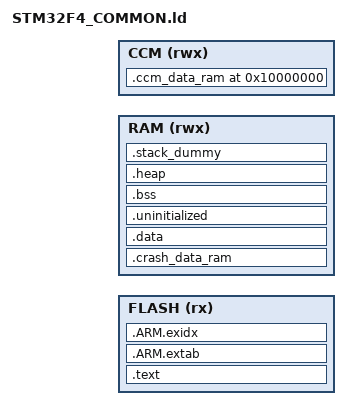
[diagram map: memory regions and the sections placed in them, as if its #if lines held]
/**
 * Copyright (c) 2026 MbedCE Community Contributors (Jan Kamidra)
 * SPDX-License-Identifier: Apache-2.0
 *
 * Licensed under the Apache License, Version 2.0 (the "License");
 * you may not use this file except in compliance with the License.
 * You may obtain a copy of the License at
 *
 *     http://www.apache.org/licenses/LICENSE-2.0
 *
 * Unless required by applicable law or agreed to in writing, software
 * distributed under the License is distributed on an "AS IS" BASIS,
 * WITHOUT WARRANTIES OR CONDITIONS OF ANY KIND, either express or implied.
 * See the License for the specific language governing permissions and
 * limitations under the License.
 *
 * Created by: Jan Kamidra with GitHub Copilot
 */

#include "cmsis_nvic.h"

M_CRASH_DATA_RAM_SIZE = 0x100;

#if !defined(MBED_CONF_TARGET_BOOT_STACK_SIZE)
    /* This value is normally defined by the tools
       to 0x1000 for bare metal and 0x400 for RTOS */
    #define MBED_CONF_TARGET_BOOT_STACK_SIZE  0x400
#endif
STACK_SIZE = MBED_CONF_TARGET_BOOT_STACK_SIZE;

/* Round up MBED_VECTTABLE_RAM_SIZE to 8 bytes */
#define MBED_VECTTABLE_RAM_SIZE  (((NVIC_NUM_VECTORS * 4) + 7) & 0xFFFFFFF8)


MEMORY
{
    FLASH (rx) : ORIGIN = MBED_CONFIGURED_ROM_BANK_ROM_START, LENGTH = MBED_CONFIGURED_ROM_BANK_ROM_SIZE
    RAM (rwx)  : ORIGIN = MBED_RAM_BANK_SRAM_START + MBED_VECTTABLE_RAM_SIZE, LENGTH = MBED_RAM_BANK_SRAM_SIZE - MBED_VECTTABLE_RAM_SIZE
#if defined(CMM_RAM)  
    CCM (rwx)  : ORIGIN = MBED_CONFIGURED_RAM_BANK_CCM_RAM_START, LENGTH = MBED_CONFIGURED_RAM_BANK_CCM_RAM_SIZE
#endif
}

/* Linker script to place sections and symbol values. Should be used together
 * with other linker script that defines memory regions FLASH and RAM.
 * It references following symbols, which must be defined in code:
 *   Reset_Handler : Entry of reset handler
 *
 * It defines following symbols, which code can use without definition:
 *   __exidx_start
 *   __exidx_end
 *   __etext
 *   __data_start__
 *   __preinit_array_start
 *   __preinit_array_end
 *   __init_array_start
 *   __init_array_end
 *   __fini_array_start
 *   __fini_array_end
 *   __data_end__
 *   __bss_start__
 *   __bss_end__
 *   __end__
 *   end
 *   __HeapLimit
 *   __StackLimit
 *   __StackTop
 *   __stack
 *   _estack
 */
ENTRY(Reset_Handler)

SECTIONS
{
    .text :
    {
        KEEP(*(.isr_vector))
        *(.text*)

        KEEP(*(.init))
        KEEP(*(.fini))

        /* .ctors */
        *crtbegin.o(.ctors)
        *crtbegin?.o(.ctors)
        *(EXCLUDE_FILE(*crtend?.o *crtend.o) .ctors)
        *(SORT(.ctors.*))
        *(.ctors)

        /* .dtors */
        *crtbegin.o(.dtors)
        *crtbegin?.o(.dtors)
        *(EXCLUDE_FILE(*crtend?.o *crtend.o) .dtors)
        *(SORT(.dtors.*))
        *(.dtors)

        *(.rodata*)

        KEEP(*(.eh_frame*))
    } > FLASH

    .ARM.extab :
    {
        *(.ARM.extab* .gnu.linkonce.armextab.*)
    } > FLASH

    __exidx_start = .;
    .ARM.exidx :
    {
        *(.ARM.exidx* .gnu.linkonce.armexidx.*)
    } > FLASH
    __exidx_end = .;

    __etext = .;
    _sidata = .;

    /**
     * CCM (core coupled memory) data RAM section.
     * The section is marked as NOLOAD so it's not loaded at runtime. This
     * ensures that the section does not affect the flash size.
     * It is usable like:
     * std::uint8_t __attribute__((section(".ccm_data_ram"))) ccm_buffer[64 * 1024];
     */
    .ccm_data_ram 0x10000000 (NOLOAD) :
    {
        /** Align on 4 byte boundary. */
        . = ALIGN(4);
        
        /** Keep the variable even if it is not referenced. */
        KEEP(*(.ccm_data_ram))
    } > CCM

    .crash_data_ram :
    {
        . = ALIGN(8);
        __CRASH_DATA_RAM__ = .;
        __CRASH_DATA_RAM_START__ = .; /* Create a global symbol at data start */
        KEEP(*(.keep.crash_data_ram))
        *(.m_crash_data_ram)     /* This is a user defined section */
        . += M_CRASH_DATA_RAM_SIZE;
        . = ALIGN(8);
        __CRASH_DATA_RAM_END__ = .; /* Define a global symbol at data end */
    } > RAM

    .data : AT (__etext)
    {
        __data_start__ = .;
        _sdata = .;
        *(vtable)
        *(.data*)

        . = ALIGN(8);
        /* preinit data */
        PROVIDE_HIDDEN (__preinit_array_start = .);
        KEEP(*(.preinit_array))
        PROVIDE_HIDDEN (__preinit_array_end = .);

        . = ALIGN(8);
        /* init data */
        PROVIDE_HIDDEN (__init_array_start = .);
        KEEP(*(SORT(.init_array.*)))
        KEEP(*(.init_array))
        PROVIDE_HIDDEN (__init_array_end = .);

        . = ALIGN(8);
        /* finit data */
        PROVIDE_HIDDEN (__fini_array_start = .);
        KEEP(*(SORT(.fini_array.*)))
        KEEP(*(.fini_array))
        PROVIDE_HIDDEN (__fini_array_end = .);

        KEEP(*(.jcr*))
        . = ALIGN(8);
        /* All data end */
        __data_end__ = .;
        _edata = .;

    } > RAM

    /* Uninitialized data section
     * This region is not initialized by the C/C++ library and can be used to
     * store state across soft reboots. */
    .uninitialized (NOLOAD):
    {
        . = ALIGN(32);
        __uninitialized_start = .;
        *(.uninitialized)
        KEEP(*(.keep.uninitialized))
        . = ALIGN(32);
        __uninitialized_end = .;
    } > RAM
    
    .bss :
    {
        . = ALIGN(8);
        __bss_start__ = .;
        _sbss = .;
        *(.bss*)
        *(COMMON)
        . = ALIGN(8);
        __bss_end__ = .;
        _ebss = .;
    } > RAM

    .heap (COPY):
    {
        __end__ = .;
        PROVIDE(end = .);
        *(.heap*)
        . = ORIGIN(RAM) + LENGTH(RAM) - STACK_SIZE;
        __HeapLimit = .;
    } > RAM

    /* .stack_dummy section doesn't contains any symbols. It is only
     * used for linker to calculate size of stack sections, and assign
     * values to stack symbols later */
    .stack_dummy (COPY):
    {
        *(.stack*)
    } > RAM

    /* Set stack top to end of RAM, and stack limit move down by
     * size of stack_dummy section */
    __StackTop = ORIGIN(RAM) + LENGTH(RAM);
    _estack = __StackTop;
    __StackLimit = __StackTop - STACK_SIZE;
    PROVIDE(__stack = __StackTop);

    /* Check if data + heap + stack exceeds RAM limit */
    ASSERT(__StackLimit >= __HeapLimit, "region RAM overflowed with stack")
}
